# STM32F429 register map
File version: 1.2
CPU: CM4 r1p0, little endian, no MPU, no FPU, 4 interrupt priority bits
Registers are 32-bit, read-write, reset 0x0 unless marked. A register's access mark holds for its fields unless they carry their own. Offsets are from the block's base; [hi:lo] are bit positions; {n}, {i} and the like mark numbered series; 'fields as' and 'values as' point back to an identical list.

## OTG_FS_PWRCLK — USB on the go full speed
Base 0x50000E00
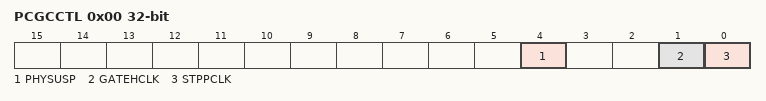
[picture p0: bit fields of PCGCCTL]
0x00 PCGCCTL — OTG_FS power and clock gating control register (OTG_FS_PCGCCTL)
  [4] PHYSUSP — PHY Suspended
  [1] GATEHCLK
  [0] STPPCLK — Stop PHY clock

## NVIC — Nested Vectored Interrupt Controller
Base 0xE000E100
{0x0+4i} ISER{i} (i=0..2) — Interrupt Set-Enable Register
  [31:0] SETENA
{0x80+4i} ICER{i} (i=0..2) — Interrupt Clear-Enable Register
  [31:0] CLRENA
{0x100+4i} ISPR{i} (i=0..2) — Interrupt Set-Pending Register
  [31:0] SETPEND
{0x180+4i} ICPR{i} (i=0..2) — Interrupt Clear-Pending Register
  [31:0] CLRPEND
{0x200+4i} IABR{i} ro (i=0..2) — Interrupt Active Bit Register
  [31:0] ACTIVE
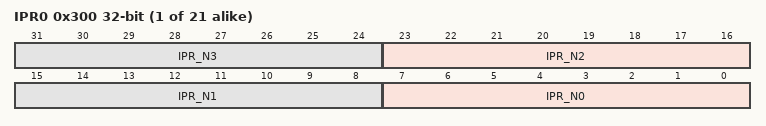
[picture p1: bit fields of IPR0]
{0x300+4i} IPR{i} (i=0..20) — Interrupt Priority Register
  [8n+7:8n] IPR_N{n} (n=0..3)

## FLASH
Base 0x40023C00
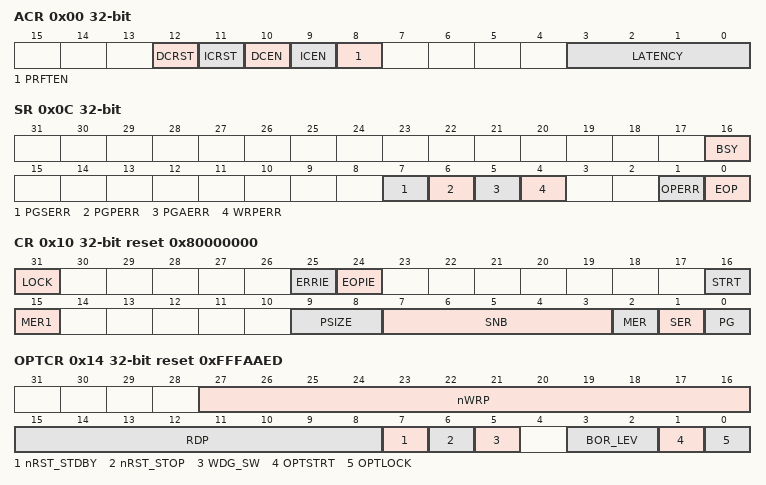
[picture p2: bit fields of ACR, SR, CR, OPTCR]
0x00 ACR access per field — Flash access control register
  [12] DCRST rw — Data cache reset
    0=NotReset (Data cache is not reset); 1=Reset (Data cache is reset)
  [11] ICRST wo — Instruction cache reset
    0=NotReset (Instruction cache is not reset); 1=Reset (Instruction cache is reset)
  [10] DCEN rw — Data cache enable
    0=Disabled (Data cache is disabled); 1=Enabled (Data cache is enabled)
  [9] ICEN rw — Instruction cache enable
    0=Disabled (Instruction cache is disabled); 1=Enabled (Instruction cache is enabled)
  [8] PRFTEN rw — Prefetch enable
    0=Disabled (Prefetch is disabled); 1=Enabled (Prefetch is enabled)
  [3:0] LATENCY rw
    {v}=WS{v} ({v} wait states) (v=0..15)
0x04 KEYR wo — Flash key register
  [31:0] KEY — FPEC key
0x08 OPTKEYR wo — Flash option key register
  [31:0] OPTKEY — Option byte key
0x0C SR access per field — Status register
  [16] BSY ro — Busy
  [7] PGSERR rw — Programming sequence error
  [6] PGPERR rw — Programming parallelism error
  [5] PGAERR rw — Programming alignment error
  [4] WRPERR rw — Write protection error
  [1] OPERR rw — Operation error
  [0] EOP rw — End of operation
0x10 CR reset 0x80000000 — Control register
  [31] LOCK
    0=Unlocked (FLASH_CR register is unlocked); 1=Locked (FLASH_CR register is locked)
  [25] ERRIE — Error interrupt enable
    0=Disabled (Error interrupt generation disabled); 1=Enabled (Error interrupt generation enabled)
  [24] EOPIE — End of operation interrupt enable
    0=Disabled (End of operation interrupt disabled); 1=Enabled (End of operation interrupt enabled)
  [16] STRT — Start
    1=Start (Trigger an erase operation)
  [15] MER1 — Mass Erase of sectors 12 to 23
  [9:8] PSIZE — Program size
    0=Program x8; 1=Program x16; 2=Program x32; 3=Program x64
  [7:3] SNB range 0..11 — Sector number
  [2] MER — Mass Erase of sectors 0 to 11
    1=MassErase (Erase activated for all user sectors)
  [1] SER — Sector Erase
    1=SectorErase (Erase activated for selected sector)
  [0] PG — Programming
    1=Program (Flash programming activated)
0x14 OPTCR reset 0xFFFAAED — Flash option control register
  [27:16] nWRP — Not write protect
  [15:8] RDP — Read protect
  [7] nRST_STDBY — nRST_STDBY User option bytes
  [6] nRST_STOP — nRST_STOP User option bytes
  [5] WDG_SW — WDG_SW User option bytes
  [3:2] BOR_LEV — BOR reset Level
  [1] OPTSTRT — Option start
  [0] OPTLOCK — Option lock
0x18 OPTCR1 reset 0xFFF0000 — Flash option control register 1
  [27:16] nWRP — Not write protect

## EXTI — External interrupt/event controller
Base 0x40013C00
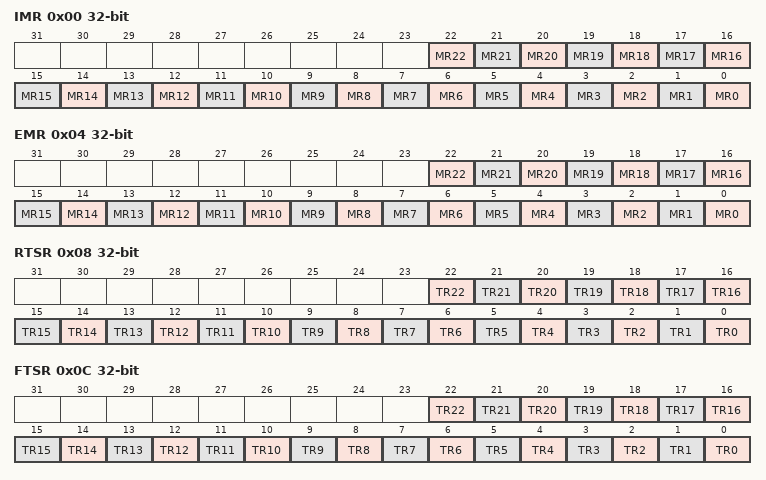
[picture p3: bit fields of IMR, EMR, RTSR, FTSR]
0x00 IMR — Interrupt mask register (EXTI_IMR)
  [all] fields
    0=Masked (Interrupt request line is masked); 1=Unmasked (Interrupt request line is unmasked)
  [n] MR{n} (n=0..22) — Interrupt Mask on line {n}
0x04 EMR — Event mask register (EXTI_EMR)
  [all] fields
    values as the fields of IMR
  [n] MR{n} (n=0..22) — Event Mask on line {n}
0x08 RTSR — Rising Trigger selection register (EXTI_RTSR)
  [all] fields
    0=Disabled (Rising edge trigger is disabled); 1=Enabled (Rising edge trigger is enabled)
  [n] TR{n} (n=0..22) — Rising trigger event configuration of line {n}
0x0C FTSR — Falling Trigger selection register (EXTI_FTSR)
  [all] fields
    0=Disabled (Falling edge trigger is disabled); 1=Enabled (Falling edge trigger is enabled)
  [n] TR{n} (n=0..22) — Falling trigger event configuration of line {n}
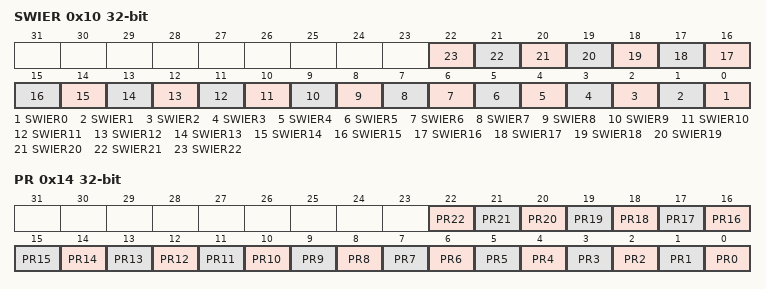
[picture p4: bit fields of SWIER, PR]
0x10 SWIER — Software interrupt event register (EXTI_SWIER)
  [all] fields
    on write: 1=Pend (Generates an interrupt request)
  [n] SWIER{n} (n=0..22) — Software Interrupt on line {n}
0x14 PR — Pending register (EXTI_PR)
  [all] fields
    on read: 0=NotPending (No trigger request occurred); 1=Pending (Selected trigger request occurred) | on write: 1=Clears pending bit
  [n] PR{n} (n=0..22) — Pending bit {n}
